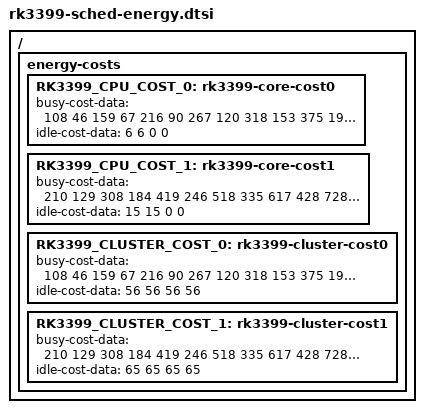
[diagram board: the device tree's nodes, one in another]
// SPDX-License-Identifier: (GPL-2.0+ OR MIT)
/*
 * Copyright (c) 2022 Rockchip Electronics Co., Ltd.
 *
 */

/ {
	energy-costs {
		RK3399_CPU_COST_0: rk3399-core-cost0 {
			busy-cost-data = <
				108    46	/*  408M */
				159    67	/*  600M */
				216    90	/*  816M */
				267    120	/* 1008M */
				318    153	/* 1200M */
				375    198	/* 1416M */
				401    222	/* 1512M */
			>;
			idle-cost-data = <
				  6
				  6
				  0
				  0
			>;
		};

		RK3399_CPU_COST_1: rk3399-core-cost1 {
			busy-cost-data = <
				210   129	/*  408MHz */
				308   184	/*  600MHz */
				419   246	/*  816MHz */
				518   335	/* 1008MHz */
				617   428	/* 1200MHz */
				728   573	/* 1416MHz */
				827   724	/* 1608MHz */
				925   900	/* 1800MHz */
				1024  1108	/* 1992MHz */
			>;
			idle-cost-data = <
				  15
				  15
				   0
				   0
			>;
		};

		RK3399_CLUSTER_COST_0: rk3399-cluster-cost0 {
			busy-cost-data = <
				108    46	/*  408M */
				159    67	/*  600M */
				216    90	/*  816M */
				267    120	/* 1008M */
				318    153	/* 1200M */
				375    198	/* 1416M */
				401    222	/* 1512M */
			>;
			idle-cost-data = <
				56
				56
				56
				56
			>;
		};

		RK3399_CLUSTER_COST_1: rk3399-cluster-cost1 {
			busy-cost-data = <
				210   129	/*  408MHz */
				308   184	/*  600MHz */
				419   246	/*  816MHz */
				518   335	/* 1008MHz */
				617   428	/* 1200MHz */
				728   573	/* 1416MHz */
				827   724	/* 1608MHz */
				925   900	/* 1800MHz */
				1024  1108	/* 1992MHz */
			>;
			idle-cost-data = <
				 65
				 65
				 65
				 65
			>;
		};
	};
};
